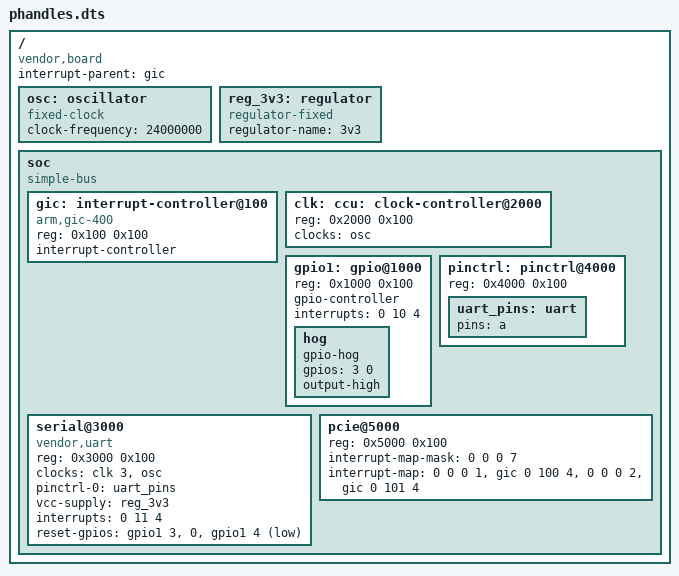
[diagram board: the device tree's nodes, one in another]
/dts-v1/;
/ {
	#address-cells = <1>;
	#size-cells = <1>;
	interrupt-parent = <&gic>;
	compatible = "vendor,board";
	osc: oscillator { compatible = "fixed-clock"; #clock-cells = <0>; clock-frequency = <24000000>; };
	reg_3v3: regulator { compatible = "regulator-fixed"; regulator-name = "3v3"; };
	soc {
		compatible = "simple-bus";
		#address-cells = <1>;
		#size-cells = <1>;
		ranges;
		gic: interrupt-controller@100 { compatible = "arm,gic-400"; reg = <0x100 0x100>; interrupt-controller; #interrupt-cells = <3>; #address-cells = <0>; };
		clk: ccu: clock-controller@2000 { reg = <0x2000 0x100>; #clock-cells = <1>; clocks = <&osc>; };
		gpio1: gpio@1000 { reg = <0x1000 0x100>; gpio-controller; #gpio-cells = <2>; interrupts = <0 10 4>;
			hog { gpio-hog; gpios = <3 0>; output-high; };
		};
		pinctrl: pinctrl@4000 { reg = <0x4000 0x100>; uart_pins: uart { pins = "a"; }; };
		serial@3000 {
			compatible = "vendor,uart";
			reg = <0x3000 0x100>;
			clocks = <&clk 3>, <&osc>;
			clock-names = "baud", "ref";
			pinctrl-0 = <&uart_pins>;
			pinctrl-names = "default";
			vcc-supply = <&reg_3v3>;
			interrupts = <0 11 4>;
			reset-gpios = <&gpio1 3 0>, <0>, <&gpio1 4 1>;
			status = "okay";
		};
		pcie@5000 {
			reg = <0x5000 0x100>;
			#address-cells = <3>;
			#size-cells = <2>;
			#interrupt-cells = <1>;
			interrupt-map-mask = <0 0 0 7>;
			interrupt-map = <0 0 0 1 &gic 0 100 4>, <0 0 0 2 &gic 0 101 4>;
		};
	};
};
